# STMP3770 register map
Vendor: Freescale Semiconductor (NXP); Series: STMP37xx; File version: 1.0
CPU: other r0p0, little endian, no MPU, no FPU, 2 interrupt priority bits
Registers are 32-bit, read-write, reset 0x0 unless marked. A register's access mark holds for its fields unless they carry their own. Offsets are from the block's base; [hi:lo] are bit positions.

## USBPHY — USB 2.0 收发 PHY 寄存器，包含电源关断、发送器/接收器控制、通用控制、状态、调试及 IP 版本等寄存器。
Base 0x8007C000
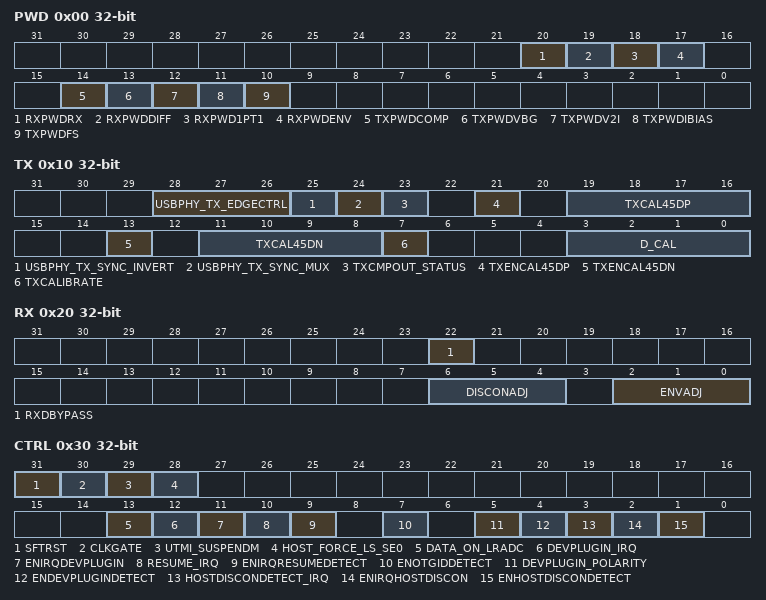
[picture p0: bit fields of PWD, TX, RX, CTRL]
0x00 PWD — USB PHY 各路电源关断控制寄存器，写 0 上电、写 1 掉电。
  [20] RXPWDRX — 整个接收器掉电控制位，写 1 掉电、写 0 上电。
  [19] RXPWDDIFF — 差分接收器掉电控制位，写 1 掉电、写 0 上电。
  [18] RXPWD1PT1 — 1.1V 接收器掉电控制位，写 1 掉电、写 0 上电。
  [17] RXPWDENV — 接收器包络检测器掉电控制位，写 1 掉电、写 0 上电。
  [14] TXPWDCOMP — 发送器比较器掉电控制位，写1掉电、写0上电。此位不使用，应保持置位。PDF标记。
  [13] TXPWDVBG — 发送器带隙参考掉电控制位，写1掉电、写0上电。STMP3770中此位无功能。PDF标记为未使用。
  [12] TXPWDV2I — 发送器压流转换器掉电控制位，写 1 掉电、写 0 上电。
  [11] TXPWDIBIAS — 发送器偏置电流源掉电控制位，写 1 掉电、写 0 上电。
  [10] TXPWDFS — 全速发送器掉电控制位，写 1 掉电、写 0 上电。
0x10 TX — USB PHY 发送器控制寄存器，负责驱动校准与端接电阻校准。
  [28:26] USBPHY_TX_EDGECTRL — 发送边沿控制字段，3 位数值，用于调整输出边沿速率。
  [25] USBPHY_TX_SYNC_INVERT — 发送同步信号反相控制位，写 1 反相。
  [24] USBPHY_TX_SYNC_MUX — 发送同步多路选择控制位。
  [23] TXCMPOUT_STATUS — 发送器比较器输出状态，只读。此位不使用。
  [21] TXENCAL45DP — D+ 线 45Ω 端接电阻校准使能位，写 1 使能。
  [19:16] TXCAL45DP — D+ 线 45Ω 端接电阻校准值，4 位无符号数。
  [13] TXENCAL45DN — D- 线 45Ω 端接电阻校准使能位，写 1 使能。
  [11:8] TXCAL45DN — D- 线 45Ω 端接电阻校准值，4 位无符号数。
  [7] TXCALIBRATE — 发送器校准控制位。此位不使用，必须保持清零。
  [3:0] D_CAL — D+/D- 输出驱动电流校准值，4 位无符号数。
0x20 RX — USB PHY 接收器控制寄存器，负责包络检测与断开检测阈值调整。
  [22] RXDBYPASS — 接收器数据旁路控制位，写 1 绕过同步/解码逻辑直接输出原始数据。
  [6:4] DISCONADJ — 断开检测阈值调整值，3 位数值。
  [2:0] ENVADJ — 接收器包络检测阈值调整值，3 位数值。
0x30 CTRL — USB PHY 通用控制寄存器，包含检测使能、中断、UTMI 挂起、时钟门控及软复位控制。
  [31] SFTRST — 软复位控制位，写 1 触发 USB PHY 软复位，写 0 释放复位。
  [30] CLKGATE — 时钟门控控制位，写 1 关闭 USB PHY 时钟以节省功耗，写 0 解除门控。
  [29] UTMI_SUSPENDM — UTMI 挂起控制位，写 1 将 PHY 置于 UTMI 挂起状态。
  [28] HOST_FORCE_LS_SE0 — 主机强制低速 SE0 控制位，写 1 在 Host 模式下强制输出低速 SE0 状态。
  [13] DATA_ON_LRADC — LRADC 数据映射使能位，写 1 将 USB 数据信号映射到低分辨率 ADC 采样。
  [12] DEVPLUGIN_IRQ — 设备插入中断状态位，写 1 清除中断标志。
  [11] ENIRQDEVPLUGIN — 设备插入中断使能位，写 1 允许设备插入事件触发中断。
  [10] RESUME_IRQ — 远程唤醒中断状态位，写 1 清除中断标志。
  [9] ENIRQRESUMEDETECT — 远程唤醒中断使能位，写 1 允许 USB 远程唤醒事件触发中断。
  [7] ENOTGIDDETECT — OTG ID 检测使能位，写 1 使能 OTG ID 引脚状态检测。
  [5] DEVPLUGIN_POLARITY — 设备插入检测极性选择位。
  [4] ENDEVPLUGINDETECT — 设备插入检测使能位，写 1 使能设备插入检测。
  [3] HOSTDISCONDETECT_IRQ — 主机断开中断状态位，写 1 清除中断标志。
  [2] ENIRQHOSTDISCON — 主机断开中断使能位，写 1 允许主机断开事件触发中断。
  [1] ENHOSTDISCONDETECT — 主机断开检测使能位，写 1 使能 Host 模式下设备断开检测。
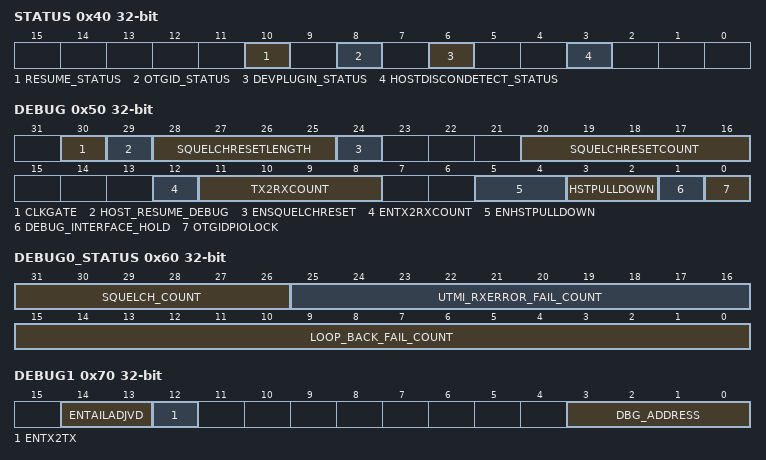
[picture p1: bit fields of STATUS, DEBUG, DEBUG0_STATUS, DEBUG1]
0x40 STATUS ro — USB PHY 状态寄存器，只读，反映主机断开、设备插入、OTG ID 及远程唤醒等事件状态。
  [10] RESUME_STATUS — 远程唤醒状态位，只读，1 表示检测到 USB 远程唤醒信号。
  [8] OTGID_STATUS — OTG ID 状态位，只读，反映 OTG ID 引脚当前电平状态。
  [6] DEVPLUGIN_STATUS — 设备插入状态位，只读，1 表示检测到 USB 设备已插入。
  [3] HOSTDISCONDETECT_STATUS — 主机断开检测状态位，只读，1 表示 Host 模式下设备已断开。
0x50 DEBUG ro — USB PHY 调试寄存器，用于调试模式下控制 OTG ID 锁定、接口保持、主机下拉、发送转接收计数及静噪复位等功能。
  [30] CLKGATE — 调试时钟门控控制位，写 1 关闭调试模块时钟，写 0 解除门控。
  [29] HOST_RESUME_DEBUG — 主机恢复调试控制位，写 1 使能主机恢复调试模式。
  [28:25] SQUELCHRESETLENGTH — 静噪复位脉冲长度，4 位数值，定义静噪复位信号的持续时间。
  [24] ENSQUELCHRESET — 静噪复位使能位，写 1 使能静噪检测复位功能。
  [20:16] SQUELCHRESETCOUNT — 静噪复位计数器阈值，5 位数值，定义检测到静噪后触发复位的计数值。
  [12] ENTX2RXCOUNT — 发送转接收计数使能位，写 1 使能 TX2RXCOUNT 计数器功能。
  [11:8] TX2RXCOUNT — 发送转接收计数器阈值，4 位数值，定义发送完成后切换到接收模式的延迟计数值。
  [5:4] ENHSTPULLDOWN — 主机下拉电阻使能字段，2 位数值，分别使能 D+/D- 线上的主机下拉电阻。
  [3:2] HSTPULLDOWN — 主机下拉电阻控制字段，2 位数值，分别控制 D+/D- 线上的主机下拉电阻。
  [1] DEBUG_INTERFACE_HOLD — 调试接口保持控制位，写 1 保持 UTMI 调试接口处于保持状态。
  [0] OTGIDPIOLOCK — OTG ID PIO 锁定控制位，写 1 锁定 OTG ID 状态到 PIO 采样值。
0x60 DEBUG0_STATUS — UTMI 调试状态寄存器 0，只读，反映环回测试、接收错误及静噪检测的计数状态。
  [31:26] SQUELCH_COUNT — 静噪计数，6 位数值，反映当前静噪检测器的状态计数值。
  [25:16] UTMI_RXERROR_FAIL_COUNT — UTMI 接收错误失败计数，10 位数值，记录 UTMI 接收错误检测的累计次数。
  [15:0] LOOP_BACK_FAIL_COUNT — 环回测试失败计数，16 位数值，记录环回测试过程中失败的次数。
0x70 DEBUG1 ro — UTMI 调试寄存器 1，用于配置调试地址、发送环回及尾码调整电压等调试功能。
  [14:13] ENTAILADJVD — 尾码调整电压控制字段，2 位数值，用于调整发送器尾码电流的电压偏置。
  [12] ENTX2TX — 发送环回使能位，写 1 使能发送器到发送器的内部环回路径。
  [3:0] DBG_ADDRESS — 调试地址字段，4 位数值，选择当前访问的 UTMI 内部调试寄存器地址。
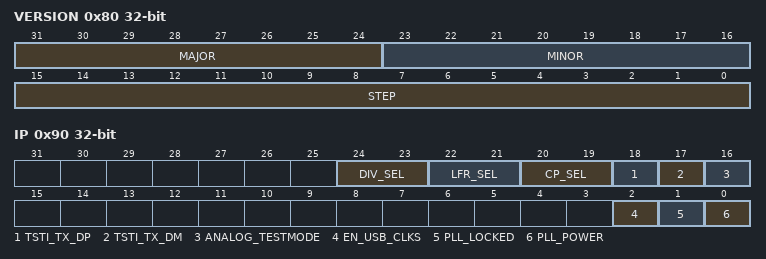
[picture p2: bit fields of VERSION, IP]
0x80 VERSION ro — UTMI RTL 版本寄存器，只读，反映当前 USB PHY IP 的 RTL 版本号。
  [31:24] MAJOR — 主版本号，8 位数值，表示 RTL 的主要版本。
  [23:16] MINOR — 次版本号，8 位数值，表示 RTL 的次要版本。
  [15:0] STEP — 步进版本号，16 位数值，表示 RTL 的步进版本。
0x90 IP — USB PHY IP 块控制寄存器，包含 PLL 电源、USB 时钟使能、模拟测试模式及 PLL 环路参数选择。
  [24:23] DIV_SEL — PLL 分频比选择字段，2 位枚举：DEFAULT(默认)、LOWER(较低)、LOWEST(最低)、UNDEFINED(未定义)。
    0=DEFAULT; 1=LOWER; 2=LOWEST; 3=UNDEFINED
  [22:21] LFR_SEL — 环路滤波电阻选择字段，2 位枚举：DEFAULT(默认)、TIMES_2(2 倍)、TIMES_05(0.5 倍)、UNDEFINED(未定义)。
    0=DEFAULT; 1=TIMES_2; 2=TIMES_05; 3=UNDEFINED
  [20:19] CP_SEL — 电荷泵电流选择字段，2 位枚举：DEFAULT(默认)、TIMES_2(2 倍)、TIMES_05(0.5 倍)、UNDEFINED(未定义)。
    0=DEFAULT; 1=TIMES_2; 2=TIMES_05; 3=UNDEFINED
  [18] TSTI_TX_DP — 模拟测试输入 D+ 控制位，写 1 将测试信号驱动到 D+ 线。
  [17] TSTI_TX_DM — 模拟测试输入 D- 控制位，写 1 将测试信号驱动到 D- 线。
  [16] ANALOG_TESTMODE — 模拟测试模式使能位，写 1 使能 USB PHY 模拟电路测试模式。
  [2] EN_USB_CLKS — USB 时钟使能位，写 1 使能 USB PHY 内部时钟输出到控制器。
  [1] PLL_LOCKED — PLL 锁定状态位，只读，1 表示 USB PHY PLL 已锁定。
  [0] PLL_POWER — PLL 电源控制位，写 1 为 USB PHY PLL 上电，写 0 掉电。
